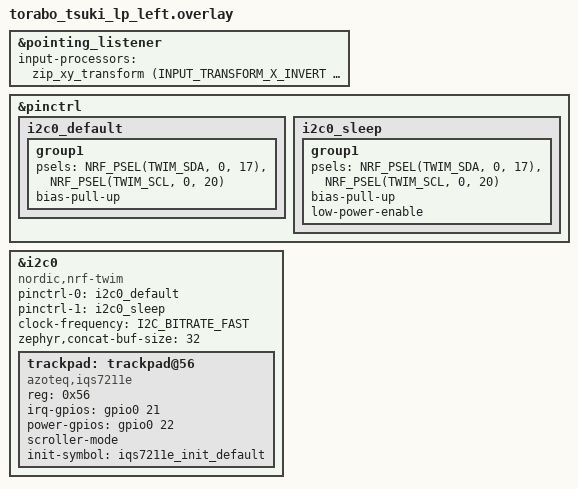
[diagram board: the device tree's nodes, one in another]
#include "torabo_tsuki_lp.dtsi"
#include <input/processors.dtsi>
#include <dt-bindings/zmk/input_transform.h>

&pointing_listener {
    input-processors = <&zip_xy_transform (INPUT_TRANSFORM_X_INVERT | INPUT_TRANSFORM_Y_INVERT)>;
};
&pinctrl {
    i2c0_default: i2c0_default {
        group1 {
            psels = <NRF_PSEL(TWIM_SDA, 0, 17)>,
                    <NRF_PSEL(TWIM_SCL, 0, 20)>;
            bias-pull-up;
        };
    };

    i2c0_sleep: i2c0_sleep {
        group1 {
            psels = <NRF_PSEL(TWIM_SDA, 0, 17)>,
                    <NRF_PSEL(TWIM_SCL, 0, 20)>;
            bias-pull-up;
            low-power-enable;
        };
    };
};

&i2c0 {
    status = "okay";
    compatible = "nordic,nrf-twim";
    pinctrl-0 = <&i2c0_default>;
    pinctrl-1 = <&i2c0_sleep>;
    pinctrl-names = "default", "sleep";
    clock-frequency = <I2C_BITRATE_FAST>;
    zephyr,concat-buf-size = <32>;

    trackpad: trackpad@56 {
        status = "okay";
        compatible = "azoteq,iqs7211e";
        reg = <0x56>;
        irq-gpios = <&gpio0 21 GPIO_PULL_UP>;
        power-gpios = <&gpio0 22 GPIO_ACTIVE_HIGH>;
        scroller-mode;
        // v-invert;
# 【追加箇所】指示書にある文字だけをそのまま配置（余計な init-length は削除）
        init-symbol = "iqs7211e_init_default";
    };
};
